# MIMXRT1062 register map
Vendor: nxp.com; File version: 1.0
CPU: CM7 r0p1, little endian, MPU, FPU, VTOR, 4 interrupt priority bits
Registers are 32-bit, read-write, reset 0x0 unless marked. A register's access mark holds for its fields unless they carry their own. Offsets are from the block's base; [hi:lo] are bit positions; 'fields as' and 'values as' point back to an identical list.

## TSC — Touch Screen Controller
Base 0x400E0000; register names take the prefix TSC_
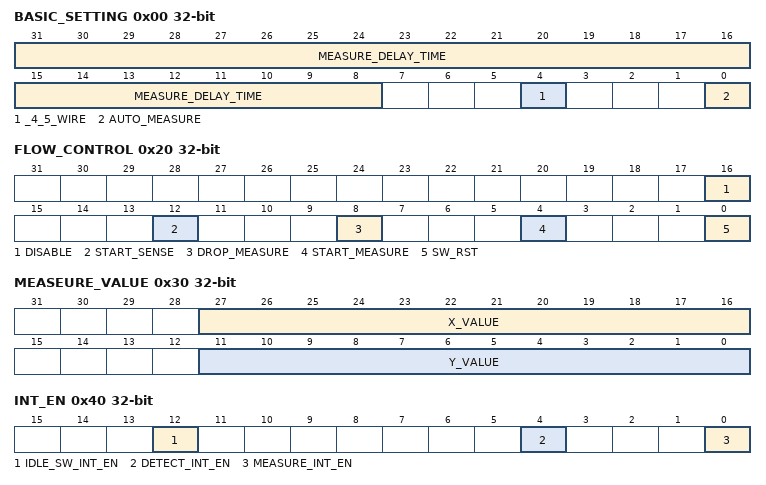
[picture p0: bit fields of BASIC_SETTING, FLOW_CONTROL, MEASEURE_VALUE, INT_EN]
0x00 BASIC_SETTING
  [31:8] MEASURE_DELAY_TIME
  [4] _4_5_WIRE — 4/5 Wire detection
    0=4_5_WIRE_0 (4-Wire Detection Mode); 1=4_5_WIRE_1 (5-Wire Detection Mode)
  [0] AUTO_MEASURE
    0=Disable Auto Measure; 1=Auto Measure
0x10 PRE_CHARGE_TIME
  [31:0] PRE_CHARGE_TIME — Before detection, the top screen needs some time before being pulled up to a high voltage.
0x20 FLOW_CONTROL
  [16] DISABLE — This bit is for SW disable registers
    0=Leave HW state machine control; 1=SW set to idle status
  [12] START_SENSE
    0=Stay at idle status; 1=Start sense detection and (if auto_measure set to 1) measure after detect a touch
  [8] DROP_MEASURE
    0=Do not drop measure for now; 1=Drop the measure and controller return to idle status
  [4] START_MEASURE
    0=Do not start measure for now; 1=Start measure the X/Y coordinate value
  [0] SW_RST — Soft Reset
0x30 MEASEURE_VALUE ro — Measure Value
  [27:16] X_VALUE, [11:0] Y_VALUE
0x40 INT_EN — Interrupt Enable
  [12] IDLE_SW_INT_EN — Idle Software Interrupt Enable
    0=Disable idle software interrupt; 1=Enable idle software interrupt
  [4] DETECT_INT_EN — Detect Interrupt Enable
    0=Disable detect interrupt; 1=Enable detect interrupt
  [0] MEASURE_INT_EN — Measure Interrupt Enable
    0=Disable measure interrupt; 1=Enable measure interrupt
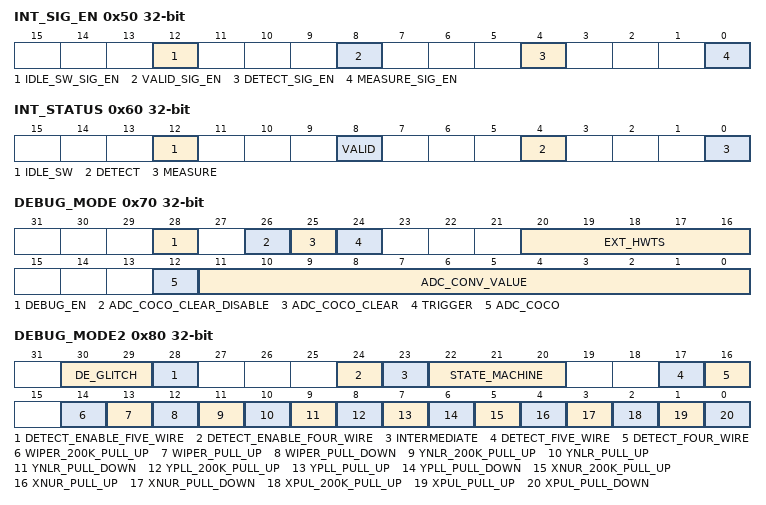
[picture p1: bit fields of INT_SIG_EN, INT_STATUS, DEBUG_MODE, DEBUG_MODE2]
0x50 INT_SIG_EN — Interrupt Signal Enable
  [12] IDLE_SW_SIG_EN — Idle Software Signal Enable
    0=Disable idle software signal; 1=Enable idle software signal
  [8] VALID_SIG_EN — Valid Signal Enable
    0=Disable valid signal; 1=Enable valid signal
  [4] DETECT_SIG_EN — Detect Signal Enable
    0=Disable detect signal; 1=Enable detect signal
  [0] MEASURE_SIG_EN — Measure Signal Enable
0x60 INT_STATUS — Intterrupt Status
  [12] IDLE_SW — Idle Software
    0=Haven't return to idle status; 1=Already return to idle status
  [8] VALID — Valid Signal
    0=There is no touch detected after measurement, indicates that the measured value is not valid; 1=There is touch detection after measurement, indicates that the measure is valid
  [4] DETECT — Detect Signal
    0=Does not exist a detect signal; 1=Exist detect signal
  [0] MEASURE — Measure Signal
    0=Does not exist a measure signal; 1=Exist a measure signal
0x70 DEBUG_MODE
  [28] DEBUG_EN — Debug Enable
    0=Enable debug mode; 1=Disable debug mode
  [26] ADC_COCO_CLEAR_DISABLE
    0=Allow TSC hardware generates ADC COCO clear; 1=Prevent TSC from generate ADC COCO clear signal
  [25] ADC_COCO_CLEAR
    0=No ADC COCO clear; 1=Set ADC COCO clear
  [24] TRIGGER
    0=No hardware trigger signal; 1=Hardware trigger signal, the signal must last at least 1 ips clock period
  [20:16] EXT_HWTS — Hardware Trigger Select Signal
  [12] ADC_COCO ro — ADC COCO Signal
  [11:0] ADC_CONV_VALUE ro — ADC Conversion Value
0x80 DEBUG_MODE2
  [30:29] DE_GLITCH ro — This field indicates glitch threshold
    0=Normal function: 0x1fff ipg clock cycles; Low power mode: 0x9 low power clock cycles; 1=Normal function: 0xfff ipg clock cycles; Low power mode: :0x7 low power clock cycles; 2=Normal function: 0x7ff ipg clock cycles; Low power mode:0x5 low power clock cycles; 3=Normal function: 0x3 ipg clock cycles; Low power mode:0x3 low power clock cycles
  [28] DETECT_ENABLE_FIVE_WIRE
    0=Do not read five wire detect value, read default value from analogue; 1=Read five wire detect status from analogue
  [24] DETECT_ENABLE_FOUR_WIRE
    0=Do not read four wire detect value, read default value from analogue; 1=Read four wire detect status from analogue
  [23] INTERMEDIATE ro — Intermediate State
    0=Not in intermedia; 1=Intermedia
  [22:20] STATE_MACHINE ro
    0=Idle; 1=Pre-charge; 2=Detect; 3=X-measure; 4=Y-measure; 5=Pre-charge; 6=Detect
  [17] DETECT_FIVE_WIRE ro
    0=No detect signal; 1=Yes, there is a detect on the touch screen
  [16] DETECT_FOUR_WIRE ro
    values as DETECT_FIVE_WIRE
  [14] WIPER_200K_PULL_UP — Wiper Wire 200K Pull Up Switch
    0=Close the switch; 1=Open up the switch
  [13] WIPER_PULL_UP — Wiper Wire Pull Up Switch
    0=Close the switch; 1=Open up the switch
  [12] WIPER_PULL_DOWN — Wiper Wire Pull Down Switch
    0=Close the switch; 1=Open up the switch
  [11] YNLR_200K_PULL_UP — YNLR Wire 200K Pull Up Switch
    0=Close the switch; 1=Open up the switch
  [10] YNLR_PULL_UP — YNLR Wire Pull Up Switch
    0=Close the switch; 1=Open up the switch
  [9] YNLR_PULL_DOWN — YNLR Wire Pull Down Switch
    0=Close the switch; 1=Open up the switch
  [8] YPLL_200K_PULL_UP — YPLL Wire 200K Pull Up Switch
    0=Close the switch; 1=Open up the switch
  [7] YPLL_PULL_UP — YPLL Wire Pull Up Switch
    0=Close the switch; 1=Open the switch
  [6] YPLL_PULL_DOWN — YPLL Wire Pull Down Switch
    0=Close the switch; 1=Open up the switch
  [5] XNUR_200K_PULL_UP — XNUR Wire 200K Pull Up Switch
    0=Close the switch; 1=Open up the switch
  [4] XNUR_PULL_UP — XNUR Wire Pull Up Switch
    0=Close the switch; 1=Open up the switch
  [3] XNUR_PULL_DOWN — XNUR Wire Pull Down Switch
    0=Close the switch; 1=Open up the switch
  [2] XPUL_200K_PULL_UP — XPUL Wire 200K Pull Up Switch
    0=Close the switch; 1=Open up the switch
  [1] XPUL_PULL_UP — XPUL Wire Pull Up Switch
    0=Close the switch; 1=Open up the switch
  [0] XPUL_PULL_DOWN — XPUL Wire Pull Down Switch
    0=Close the switch; 1=Open up the switch
